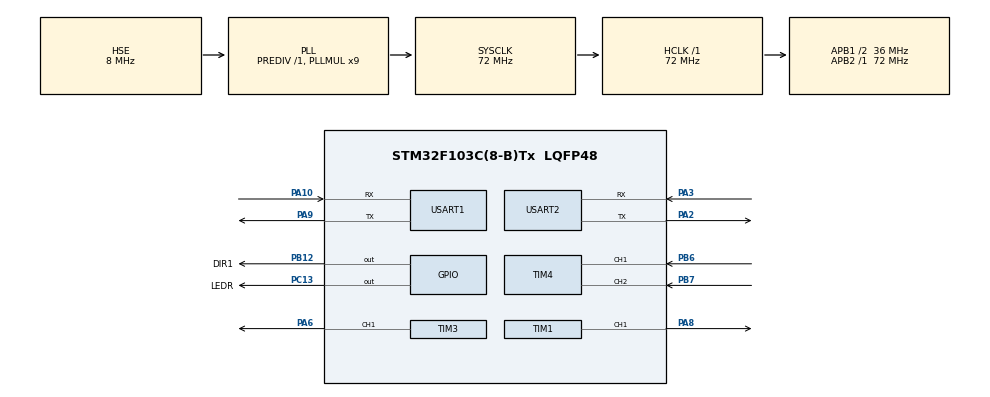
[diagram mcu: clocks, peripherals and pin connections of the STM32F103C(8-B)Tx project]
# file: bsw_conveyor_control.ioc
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Dma.Request0=USART1_TX
Dma.Request1=USART1_RX
Dma.USART1_RX.1.Direction=DMA_PERIPH_TO_MEMORY
Dma.USART1_RX.1.Instance=DMA1_Channel5
Dma.USART1_RX.1.MemDataAlignment=DMA_MDATAALIGN_BYTE
Dma.USART1_RX.1.MemInc=DMA_MINC_ENABLE
Dma.USART1_RX.1.Mode=DMA_CIRCULAR
Dma.USART1_RX.1.PeriphDataAlignment=DMA_PDATAALIGN_BYTE
Dma.USART1_RX.1.PeriphInc=DMA_PINC_DISABLE
Dma.USART1_RX.1.Priority=DMA_PRIORITY_LOW
Dma.USART1_TX.0.Direction=DMA_MEMORY_TO_PERIPH
Dma.USART1_TX.0.Instance=DMA1_Channel4
Dma.USART1_TX.0.MemDataAlignment=DMA_MDATAALIGN_BYTE
Dma.USART1_TX.0.MemInc=DMA_MINC_ENABLE
Dma.USART1_TX.0.Mode=DMA_NORMAL
Dma.USART1_TX.0.PeriphDataAlignment=DMA_PDATAALIGN_BYTE
Dma.USART1_TX.0.PeriphInc=DMA_PINC_DISABLE
Dma.USART1_TX.0.Priority=DMA_PRIORITY_MEDIUM
FREERTOS.Tasks01=defaultTask,24,128,StartDefaultTask,Default,NULL,Dynamic,NULL,NULL
FREERTOS.configCHECK_FOR_STACK_OVERFLOW=2
FREERTOS.configTOTAL_HEAP_SIZE=4096
FREERTOS.configUSE_MALLOC_FAILED_HOOK=1
Mcu.Family=STM32F1
Mcu.Name=STM32F103C(8-B)Tx
Mcu.Package=LQFP48
NVIC.DMA1_Channel4_IRQn=true\:5\:0\:false\:false\:true\:true\:false\:true\:true
NVIC.DMA1_Channel5_IRQn=true\:5\:0\:false\:false\:true\:true\:false\:true\:true
NVIC.PriorityGroup=NVIC_PRIORITYGROUP_4
NVIC.USART1_IRQn=true\:5\:0\:false\:false\:true\:true\:true\:true\:true
PA10.GPIO_PuPd=GPIO_PULLUP
PA10.Mode=Asynchronous
PA10.Signal=USART1_RX
PA13.Mode=Serial_Wire
PA13.Signal=SYS_JTMS-SWDIO
PA14.Mode=Serial_Wire
PA14.Signal=SYS_JTCK-SWCLK
PA2.Mode=Asynchronous
PA2.Signal=USART2_TX
PA3.Mode=Asynchronous
PA3.Signal=USART2_RX
PA6.Signal=S_TIM3_CH1
PA8.Signal=S_TIM1_CH1
PA9.Mode=Asynchronous
PA9.Signal=USART1_TX
PB12.GPIO_Label=DIR1
PB12.Signal=GPIO_Output
PB6.GPIO_PuPd=GPIO_NOPULL
PB6.Signal=S_TIM4_CH1
PB7.GPIO_PuPd=GPIO_NOPULL
PB7.Signal=S_TIM4_CH2
PC13-TAMPER-RTC.GPIO_Label=LEDR
PC13-TAMPER-RTC.Signal=GPIO_Output
PD0-OSC_IN.Mode=HSE-External-Oscillator
PD0-OSC_IN.Signal=RCC_OSC_IN
PD1-OSC_OUT.Mode=HSE-External-Oscillator
PD1-OSC_OUT.Signal=RCC_OSC_OUT
ProjectManager.HeapSize=0x200
ProjectManager.StackSize=0x400
ProjectManager.TargetToolchain=STM32CubeIDE
RCC.AHBFreq_Value=72000000
RCC.APB1CLKDivider=RCC_HCLK_DIV2
RCC.APB1Freq_Value=36000000
RCC.APB1TimFreq_Value=72000000
RCC.APB2Freq_Value=72000000
RCC.APB2TimFreq_Value=72000000
RCC.HCLKFreq_Value=72000000
RCC.PLLMUL=RCC_PLL_MUL9
RCC.PLLSourceVirtual=RCC_PLLSOURCE_HSE
RCC.SYSCLKFreq_VALUE=72000000
RCC.SYSCLKSource=RCC_SYSCLKSOURCE_PLLCLK
RCC.USBFreq_Value=72000000
SH.S_TIM1_CH1.0=TIM1_CH1,PWM Generation1 CH1
SH.S_TIM3_CH1.0=TIM3_CH1,PWM Generation1 CH1
SH.S_TIM4_CH1.0=TIM4_CH1,Encoder_Interface
SH.S_TIM4_CH2.0=TIM4_CH2,Encoder_Interface
TIM1.AutoReloadPreload=TIM_AUTORELOAD_PRELOAD_DISABLE
TIM1.Channel-PWM\ Generation1\ CH1=TIM_CHANNEL_1
TIM1.Period=19999
TIM1.Prescaler=71
TIM1.Pulse-PWM\ Generation1\ CH1=1500
TIM3.AutoReloadPreload=TIM_AUTORELOAD_PRELOAD_ENABLE
TIM3.Channel-PWM\ Generation1\ CH1=TIM_CHANNEL_1
TIM3.Period=3599
TIM4.EncoderMode=TIM_ENCODERMODE_TI12
TIM4.IC1Filter=15
TIM4.IC2Filter=15
USART1.VirtualMode=VM_ASYNC
USART2.VirtualMode=VM_ASYNC
VP_FREERTOS_VS_CMSIS_V2.Mode=CMSIS_V2
VP_TIM1_VS_ClockSourceINT.Mode=Internal
VP_TIM3_VS_ClockSourceINT.Mode=Internal
board=custom

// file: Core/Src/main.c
/* USER CODE BEGIN Header */
/**
  ******************************************************************************
  * @file           : main.c
  * @brief          : Main program body
  ******************************************************************************
  * @attention
  *
  * Copyright (c) 2026 STMicroelectronics.
  * All rights reserved.
  *
  * This software is licensed under terms that can be found in the LICENSE file
  * in the root directory of this software component.
  * If no LICENSE file comes with this software, it is provided AS-IS.
  *
  ******************************************************************************
  */
/* USER CODE END Header */
#include "main.h"
#include "cmsis_os.h"

/* USER CODE BEGIN Includes */
#include "tasks.h"
/* USER CODE END Includes */

TIM_HandleTypeDef htim1;
TIM_HandleTypeDef htim3;
TIM_HandleTypeDef htim4;

UART_HandleTypeDef huart1;
UART_HandleTypeDef huart2;
DMA_HandleTypeDef hdma_usart1_tx;
DMA_HandleTypeDef hdma_usart1_rx;

/* Definitions for defaultTask */
osThreadId_t defaultTaskHandle;
const osThreadAttr_t defaultTask_attributes = {
  .name = "defaultTask",
  .stack_size = 128 * 4,
  .priority = (osPriority_t) osPriorityNormal,
};

void SystemClock_Config(void);
static void MX_GPIO_Init(void);
static void MX_DMA_Init(void);
static void MX_TIM1_Init(void);
static void MX_TIM3_Init(void);
static void MX_USART1_UART_Init(void);
static void MX_USART2_UART_Init(void);
static void MX_TIM4_Init(void);
void StartDefaultTask(void *argument);

int main(void)
{

  /* MCU Configuration--------------------------------------------------------*/

  /* Reset of all peripherals, Initializes the Flash interface and the Systick. */
  HAL_Init();

  /* Configure the system clock */
  SystemClock_Config();

  /* Initialize all configured peripherals */
  MX_GPIO_Init();
  MX_DMA_Init();
  MX_TIM1_Init();
  MX_TIM3_Init();
  MX_USART1_UART_Init();
  MX_USART2_UART_Init();
  MX_TIM4_Init();

  /* Init scheduler */
  osKernelInitialize();

  /* Create the thread(s) */
  /* creation of defaultTask */
  defaultTaskHandle = osThreadNew(StartDefaultTask, NULL, &defaultTask_attributes);

  /* USER CODE BEGIN RTOS_THREADS */
  app_init(); /* static tasks, queues, stream buffer (native FreeRTOS) */
  /* USER CODE END RTOS_THREADS */

  /* Start scheduler */
  osKernelStart();

  /* We should never get here as control is now taken by the scheduler */

  /* Infinite loop */
  while (1)
  {

  }
}

void SystemClock_Config(void)
{
  RCC_OscInitTypeDef RCC_OscInitStruct = {0};
  RCC_ClkInitTypeDef RCC_ClkInitStruct = {0};

  /** Initializes the RCC Oscillators according to the specified parameters
  * in the RCC_OscInitTypeDef structure.
  */
  RCC_OscInitStruct.OscillatorType = RCC_OSCILLATORTYPE_HSE;
  RCC_OscInitStruct.HSEState = RCC_HSE_ON;
  RCC_OscInitStruct.HSEPredivValue = RCC_HSE_PREDIV_DIV1;
  RCC_OscInitStruct.HSIState = RCC_HSI_ON;
  RCC_OscInitStruct.PLL.PLLState = RCC_PLL_ON;
  RCC_OscInitStruct.PLL.PLLSource = RCC_PLLSOURCE_HSE;
  RCC_OscInitStruct.PLL.PLLMUL = RCC_PLL_MUL9;
  if (HAL_RCC_OscConfig(&RCC_OscInitStruct) != HAL_OK)
  {
    Error_Handler();
  }

  /** Initializes the CPU, AHB and APB buses clocks
  */
  RCC_ClkInitStruct.ClockType = RCC_CLOCKTYPE_HCLK|RCC_CLOCKTYPE_SYSCLK
                              |RCC_CLOCKTYPE_PCLK1|RCC_CLOCKTYPE_PCLK2;
  RCC_ClkInitStruct.SYSCLKSource = RCC_SYSCLKSOURCE_PLLCLK;
  RCC_ClkInitStruct.AHBCLKDivider = RCC_SYSCLK_DIV1;
  RCC_ClkInitStruct.APB1CLKDivider = RCC_HCLK_DIV2;
  RCC_ClkInitStruct.APB2CLKDivider = RCC_HCLK_DIV1;

  if (HAL_RCC_ClockConfig(&RCC_ClkInitStruct, FLASH_LATENCY_2) != HAL_OK)
  {
    Error_Handler();
  }
}

static void MX_TIM1_Init(void)
{

  TIM_ClockConfigTypeDef sClockSourceConfig = {0};
  TIM_MasterConfigTypeDef sMasterConfig = {0};
  TIM_OC_InitTypeDef sConfigOC = {0};
  TIM_BreakDeadTimeConfigTypeDef sBreakDeadTimeConfig = {0};

  htim1.Instance = TIM1;
  htim1.Init.Prescaler = 71;
  htim1.Init.CounterMode = TIM_COUNTERMODE_UP;
  htim1.Init.Period = 19999;
  htim1.Init.ClockDivision = TIM_CLOCKDIVISION_DIV1;
  htim1.Init.RepetitionCounter = 0;
  htim1.Init.AutoReloadPreload = TIM_AUTORELOAD_PRELOAD_DISABLE;
  if (HAL_TIM_Base_Init(&htim1) != HAL_OK)
  {
    Error_Handler();
  }
  sClockSourceConfig.ClockSource = TIM_CLOCKSOURCE_INTERNAL;
  if (HAL_TIM_ConfigClockSource(&htim1, &sClockSourceConfig) != HAL_OK)
  {
    Error_Handler();
  }
  if (HAL_TIM_PWM_Init(&htim1) != HAL_OK)
  {
    Error_Handler();
  }
  sMasterConfig.MasterOutputTrigger = TIM_TRGO_RESET;
  sMasterConfig.MasterSlaveMode = TIM_MASTERSLAVEMODE_DISABLE;
  if (HAL_TIMEx_MasterConfigSynchronization(&htim1, &sMasterConfig) != HAL_OK)
  {
    Error_Handler();
  }
  sConfigOC.OCMode = TIM_OCMODE_PWM1;
  sConfigOC.Pulse = 1500;
  sConfigOC.OCPolarity = TIM_OCPOLARITY_HIGH;
  sConfigOC.OCNPolarity = TIM_OCNPOLARITY_HIGH;
  sConfigOC.OCFastMode = TIM_OCFAST_DISABLE;
  sConfigOC.OCIdleState = TIM_OCIDLESTATE_RESET;
  sConfigOC.OCNIdleState = TIM_OCNIDLESTATE_RESET;
  if (HAL_TIM_PWM_ConfigChannel(&htim1, &sConfigOC, TIM_CHANNEL_1) != HAL_OK)
  {
    Error_Handler();
  }
  sBreakDeadTimeConfig.OffStateRunMode = TIM_OSSR_DISABLE;
  sBreakDeadTimeConfig.OffStateIDLEMode = TIM_OSSI_DISABLE;
  sBreakDeadTimeConfig.LockLevel = TIM_LOCKLEVEL_OFF;
  sBreakDeadTimeConfig.DeadTime = 0;
  sBreakDeadTimeConfig.BreakState = TIM_BREAK_DISABLE;
  sBreakDeadTimeConfig.BreakPolarity = TIM_BREAKPOLARITY_HIGH;
  sBreakDeadTimeConfig.AutomaticOutput = TIM_AUTOMATICOUTPUT_DISABLE;
  if (HAL_TIMEx_ConfigBreakDeadTime(&htim1, &sBreakDeadTimeConfig) != HAL_OK)
  {
    Error_Handler();
  }
  HAL_TIM_MspPostInit(&htim1);

}

static void MX_TIM3_Init(void)
{

  TIM_ClockConfigTypeDef sClockSourceConfig = {0};
  TIM_MasterConfigTypeDef sMasterConfig = {0};
  TIM_OC_InitTypeDef sConfigOC = {0};

  htim3.Instance = TIM3;
  htim3.Init.Prescaler = 0;
  htim3.Init.CounterMode = TIM_COUNTERMODE_UP;
  htim3.Init.Period = 3599;
  htim3.Init.ClockDivision = TIM_CLOCKDIVISION_DIV1;
  htim3.Init.AutoReloadPreload = TIM_AUTORELOAD_PRELOAD_ENABLE;
  if (HAL_TIM_Base_Init(&htim3) != HAL_OK)
  {
    Error_Handler();
  }
  sClockSourceConfig.ClockSource = TIM_CLOCKSOURCE_INTERNAL;
  if (HAL_TIM_ConfigClockSource(&htim3, &sClockSourceConfig) != HAL_OK)
  {
    Error_Handler();
  }
  if (HAL_TIM_PWM_Init(&htim3) != HAL_OK)
  {
    Error_Handler();
  }
  sMasterConfig.MasterOutputTrigger = TIM_TRGO_RESET;
  sMasterConfig.MasterSlaveMode = TIM_MASTERSLAVEMODE_DISABLE;
  if (HAL_TIMEx_MasterConfigSynchronization(&htim3, &sMasterConfig) != HAL_OK)
  {
    Error_Handler();
  }
  sConfigOC.OCMode = TIM_OCMODE_PWM1;
  sConfigOC.Pulse = 0;
  sConfigOC.OCPolarity = TIM_OCPOLARITY_HIGH;
  sConfigOC.OCFastMode = TIM_OCFAST_DISABLE;
  if (HAL_TIM_PWM_ConfigChannel(&htim3, &sConfigOC, TIM_CHANNEL_1) != HAL_OK)
  {
    Error_Handler();
  }
  HAL_TIM_MspPostInit(&htim3);

}

static void MX_TIM4_Init(void)
{

  TIM_Encoder_InitTypeDef sConfig = {0};
  TIM_MasterConfigTypeDef sMasterConfig = {0};

  htim4.Instance = TIM4;
  htim4.Init.Prescaler = 0;
  htim4.Init.CounterMode = TIM_COUNTERMODE_UP;
  htim4.Init.Period = 65535;
  htim4.Init.ClockDivision = TIM_CLOCKDIVISION_DIV1;
  htim4.Init.AutoReloadPreload = TIM_AUTORELOAD_PRELOAD_DISABLE;
  sConfig.EncoderMode = TIM_ENCODERMODE_TI12;
  sConfig.IC1Polarity = TIM_ICPOLARITY_RISING;
  sConfig.IC1Selection = TIM_ICSELECTION_DIRECTTI;
  sConfig.IC1Prescaler = TIM_ICPSC_DIV1;
  sConfig.IC1Filter = 15;
  sConfig.IC2Polarity = TIM_ICPOLARITY_RISING;
  sConfig.IC2Selection = TIM_ICSELECTION_DIRECTTI;
  sConfig.IC2Prescaler = TIM_ICPSC_DIV1;
  sConfig.IC2Filter = 15;
  if (HAL_TIM_Encoder_Init(&htim4, &sConfig) != HAL_OK)
  {
    Error_Handler();
  }
  sMasterConfig.MasterOutputTrigger = TIM_TRGO_RESET;
  sMasterConfig.MasterSlaveMode = TIM_MASTERSLAVEMODE_DISABLE;
  if (HAL_TIMEx_MasterConfigSynchronization(&htim4, &sMasterConfig) != HAL_OK)
  {
    Error_Handler();
  }

}

static void MX_USART1_UART_Init(void)
{

  huart1.Instance = USART1;
  huart1.Init.BaudRate = 115200;
  huart1.Init.WordLength = UART_WORDLENGTH_8B;
  huart1.Init.StopBits = UART_STOPBITS_1;
  huart1.Init.Parity = UART_PARITY_NONE;
  huart1.Init.Mode = UART_MODE_TX_RX;
  huart1.Init.HwFlowCtl = UART_HWCONTROL_NONE;
  huart1.Init.OverSampling = UART_OVERSAMPLING_16;
  if (HAL_UART_Init(&huart1) != HAL_OK)
  {
    Error_Handler();
  }

}

static void MX_USART2_UART_Init(void)
{

  huart2.Instance = USART2;
  huart2.Init.BaudRate = 115200;
  huart2.Init.WordLength = UART_WORDLENGTH_8B;
  huart2.Init.StopBits = UART_STOPBITS_1;
  huart2.Init.Parity = UART_PARITY_NONE;
  huart2.Init.Mode = UART_MODE_TX_RX;
  huart2.Init.HwFlowCtl = UART_HWCONTROL_NONE;
  huart2.Init.OverSampling = UART_OVERSAMPLING_16;
  if (HAL_UART_Init(&huart2) != HAL_OK)
  {
    Error_Handler();
  }

}

static void MX_DMA_Init(void)
{

  /* DMA controller clock enable */
  __HAL_RCC_DMA1_CLK_ENABLE();

  /* DMA interrupt init */
  /* DMA1_Channel4_IRQn interrupt configuration */
  HAL_NVIC_SetPriority(DMA1_Channel4_IRQn, 5, 0);
  HAL_NVIC_EnableIRQ(DMA1_Channel4_IRQn);
  /* DMA1_Channel5_IRQn interrupt configuration */
  HAL_NVIC_SetPriority(DMA1_Channel5_IRQn, 5, 0);
  HAL_NVIC_EnableIRQ(DMA1_Channel5_IRQn);

}

static void MX_GPIO_Init(void)
{
  GPIO_InitTypeDef GPIO_InitStruct = {0};

  /* GPIO Ports Clock Enable */
  __HAL_RCC_GPIOC_CLK_ENABLE();
  __HAL_RCC_GPIOD_CLK_ENABLE();
  __HAL_RCC_GPIOA_CLK_ENABLE();
  __HAL_RCC_GPIOB_CLK_ENABLE();

  /*Configure GPIO pin Output Level */
  HAL_GPIO_WritePin(LEDR_GPIO_Port, LEDR_Pin, GPIO_PIN_RESET);

  /*Configure GPIO pin Output Level */
  HAL_GPIO_WritePin(DIR1_GPIO_Port, DIR1_Pin, GPIO_PIN_RESET);

  /*Configure GPIO pin : LEDR_Pin */
  GPIO_InitStruct.Pin = LEDR_Pin;
  GPIO_InitStruct.Mode = GPIO_MODE_OUTPUT_PP;
  GPIO_InitStruct.Pull = GPIO_NOPULL;
  GPIO_InitStruct.Speed = GPIO_SPEED_FREQ_LOW;
  HAL_GPIO_Init(LEDR_GPIO_Port, &GPIO_InitStruct);

  /*Configure GPIO pin : DIR1_Pin */
  GPIO_InitStruct.Pin = DIR1_Pin;
  GPIO_InitStruct.Mode = GPIO_MODE_OUTPUT_PP;
  GPIO_InitStruct.Pull = GPIO_NOPULL;
  GPIO_InitStruct.Speed = GPIO_SPEED_FREQ_LOW;
  HAL_GPIO_Init(DIR1_GPIO_Port, &GPIO_InitStruct);

}

void StartDefaultTask(void *argument)
{
  /* USER CODE BEGIN 5 */
  osThreadExit(); /* unused: the application tasks are created in app_init() */
  /* USER CODE END 5 */
}

void Error_Handler(void)
{
  /* USER CODE BEGIN Error_Handler_Debug */
  app_fault(); /* motors off, LED on, halt */
  /* USER CODE END Error_Handler_Debug */
}

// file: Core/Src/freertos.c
/* USER CODE BEGIN Header */
/**
  ******************************************************************************
  * File Name          : freertos.c
  * Description        : Code for freertos applications
  ******************************************************************************
  * @attention
  *
  * Copyright (c) 2026 STMicroelectronics.
  * All rights reserved.
  *
  * This software is licensed under terms that can be found in the LICENSE file
  * in the root directory of this software component.
  * If no LICENSE file comes with this software, it is provided AS-IS.
  *
  ******************************************************************************
  */
/* USER CODE END Header */

#include "FreeRTOS.h"
#include "task.h"
#include "main.h"

/* USER CODE BEGIN Includes */
#include "tasks.h"
/* USER CODE END Includes */

/* Hook prototypes */
void vApplicationStackOverflowHook(xTaskHandle xTask, signed char *pcTaskName);
void vApplicationMallocFailedHook(void);

/* USER CODE BEGIN 4 */
void vApplicationStackOverflowHook(xTaskHandle xTask, signed char *pcTaskName)
{
   (void)xTask;
   (void)pcTaskName;
   app_fault();
}
/* USER CODE END 4 */

/* USER CODE BEGIN 5 */
void vApplicationMallocFailedHook(void)
{
   /* vApplicationMallocFailedHook() will only be called if
   configUSE_MALLOC_FAILED_HOOK is set to 1 in FreeRTOSConfig.h. It is a hook
   function that will get called if a call to pvPortMalloc() fails.
   pvPortMalloc() is called internally by the kernel whenever a task, queue,
   timer or semaphore is created. It is also called by various parts of the
   demo application. If heap_1.c or heap_2.c are used, then the size of the
   heap available to pvPortMalloc() is defined by configTOTAL_HEAP_SIZE in
   FreeRTOSConfig.h, and the xPortGetFreeHeapSize() API function can be used
   to query the size of free heap space that remains (although it does not
   provide information on how the remaining heap might be fragmented). */
   app_fault();
}
/* USER CODE END 5 */
